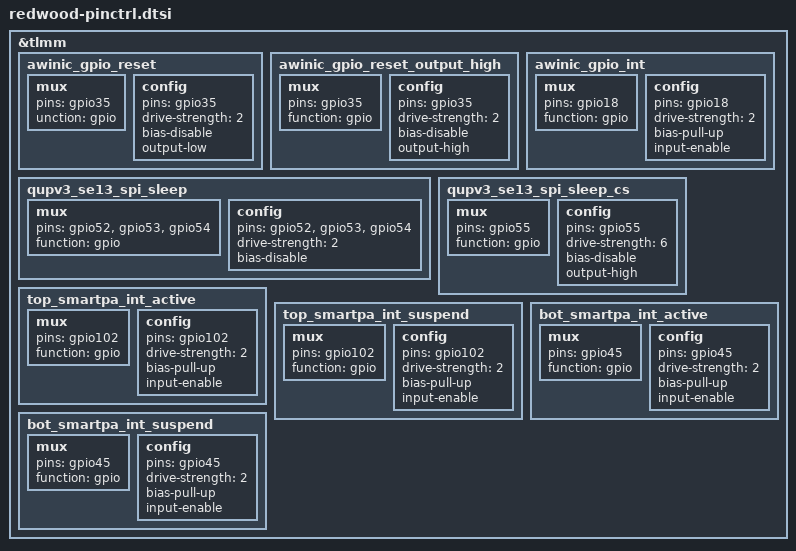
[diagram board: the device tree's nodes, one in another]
&tlmm {
	/* AW8697_RESET_N */
	awinic_gpio_reset: awinic_gpio_reset {
		mux {
			pins = "gpio35";
			unction = "gpio";
		};

		config {
			pins = "gpio35";
			drive-strength = <2>;
			bias-disable;
			output-low;
		};
	};

	/* AW8697_RESET_N, state device active*/
	awinic_gpio_reset_output_high: awinic_gpio_reset_output_high {
		mux {
			pins = "gpio35";
			function = "gpio";
		};

		config {
			pins = "gpio35";
			drive-strength = <2>;
			bias-disable;
			output-high;
		};
	};

	/* AW8697_INTERRUPT_N */
	awinic_gpio_int: awinic_gpio_int {
		mux {
			pins = "gpio18";
			function = "gpio";
		};

		config {
			pins = "gpio18";
			drive-strength = <2>;
			bias-pull-up;
			input-enable;
		};
	};

	qupv3_se13_spi_sleep: qupv3_se13_spi_sleep {
		mux {
			pins = "gpio52", "gpio53", "gpio54";
			function = "gpio";
		};

		config {
			pins = "gpio52", "gpio53", "gpio54";
			drive-strength = <2>;
			bias-disable;
		};
	};

	qupv3_se13_spi_sleep_cs: qupv3_se13_spi_sleep_cs {
		mux {
			pins = "gpio55";
			function = "gpio";
		};

		config {
			pins = "gpio55";
			drive-strength = <6>;
			bias-disable;
			output-high;
		};
	};

	top_smartpa_int_active: top_smartpa_int_active {
		/* active state */
		mux {
		/* GPIO 102 Interrupt */
			pins = "gpio102";
			function = "gpio";
		};

		config {
			pins = "gpio102";
			drive-strength = <2>; /* 2 MA */
			bias-pull-up;
			input-enable;
		};
	};

	top_smartpa_int_suspend: top_smartpa_int_suspend {
		/* sleep state */
		mux {
		/* GPIO 102 Interrupt */
			pins = "gpio102";
			function = "gpio";
		};

		config {
			pins = "gpio102";
			drive-strength = <2>; /* 2 MA */
			bias-pull-up;
			input-enable;
		};
	};

	bot_smartpa_int_active: bot_smartpa_int_active {
		/* active state */
		mux {
		/* GPIO 45 Interrupt */
			pins = "gpio45";
			function = "gpio";
		};

		config {
			pins = "gpio45";
			drive-strength = <2>; /* 2 MA */
			bias-pull-up;
			input-enable;
		};
	};

	bot_smartpa_int_suspend: bot_smartpa_int_suspend {
		/* sleep state */
		mux {
		/* GPIO 45 Interrupt */
			pins = "gpio45";
			function = "gpio";
		};

		config {
			pins = "gpio45";
			drive-strength = <2>; /* 2 MA */
			bias-pull-up;
			input-enable;
		};
	};
};
